# ADSP-SC83xW_HPC register map
Vendor: Analog Devices; Series: ADSP-SC83xW_HPC; File version: 3.0.3.517
CPU: 
Registers are 32-bit, read-write, reset 0x0 unless marked. A register's access mark holds for its fields unless they carry their own. Offsets are from the block's base; [hi:lo] are bit positions; {n}, {i} and the like mark numbered series; 'fields as' and 'values as' point back to an identical list.

## EMAC0 (part 4 of 4) — RGMII, RMII, MII Ethernet Controller
Base 0x31040000
{0xB80+0x10*i} PPS[{i}]_TGTM_SEC (i=0..3) — PPS n Target Time Seconds Register
  [31:0] TSTRH range 0x00000000..0xFFFFFFFF — PPS Target Time Seconds Register
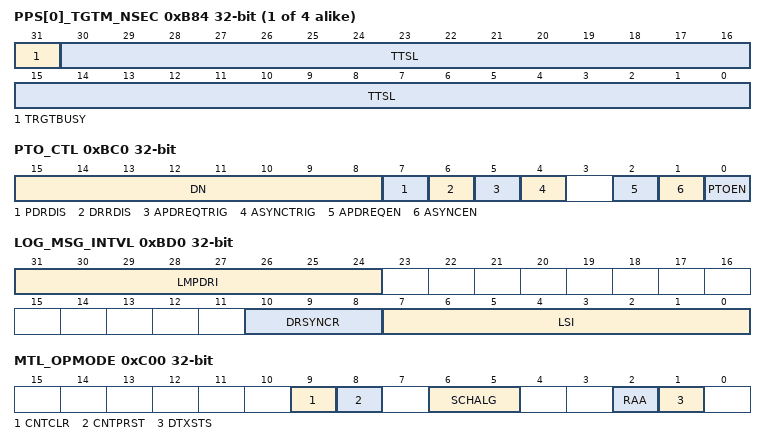
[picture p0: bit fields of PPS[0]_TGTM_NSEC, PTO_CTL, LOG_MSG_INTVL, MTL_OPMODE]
{0xB84+0x10*i} PPS[{i}]_TGTM_NSEC (i=0..3) — PPS n Target Time Nanoseconds Register
  [31] TRGTBUSY — PPS Target Time Register Busy
    0=TRGTBUSY0_INACTIVE (PPS Target Time Register Busy Status is Not Detected); 1=TRGTBUSY0_ACTIVE (PPS Target Time Register Busy is Detected)
  [30:0] TTSL range 0x00000000..0x7FFFFFFF — Target Time Low for PPS Register
{0xB88+0x10*i} PPS[{i}]_INTVL (i=0..3) — PPS n Interval Register
  [31:0] PPSINT range 0x00000000..0xFFFFFFFF — PPS Output Signal Interval
{0xB8C+0x10*i} PPS[{i}]_WID (i=0..3) — PPS n Width Register
  [31:0] PPSWIDTH range 0x00000000..0xFFFFFFFF — PPS Output Signal Width
0xBC0 PTO_CTL — PTP Time Stamp Offload Control Register
  [15:8] DN range 0x00000000..0x000000FF — Domain Number
  [7] PDRDIS — Disable Peer Delay Response Response Generation
    0=PDRDIS_ENABLE (Peer Delay Response Response Generation is Enabled); 1=PDRDIS_DISABLE (Peer Delay Response Response Generation is Disabled)
  [6] DRRDIS — Disable PTO Delay Request/Response Response Generation
    0=DRRDIS_ENABLE (PTO Delay Request/Response Response Generation is Enabled); 1=DRRDIS_DISABLE (PTO Delay Request/Response Response Generation is Disabled)
  [5] APDREQTRIG — Automatic PTP Pdelay_Req Message Trigger
    0=APDREQTRIG_DISABLE (Automatic PTP Pdelay_Req Message Trigger is Disabled); 1=APDREQTRIG_ENABLE (Automatic PTP Pdelay_Req Message Trigger is Enabled)
  [4] ASYNCTRIG — Automatic PTP SYNC Message Trigger
    0=ASYNCTRIG_DISABLE (Automatic PTP SYNC Message Trigger is Disabled); 1=ASYNCTRIG_ENABLE (Automatic PTP SYNC Message Trigger is Enabled)
  [2] APDREQEN — Automatic PTP Pdelay_Req Message Enable
    0=APDREQEN_DISABLE (Automatic PTP Pdelay_Req Message is Disabled); 1=APDREQEN_ENABLE (Automatic PTP Pdelay_Req Message is Enabled)
  [1] ASYNCEN — Automatic PTP SYNC Message Enable
    0=ASYNCEN_DISABLE (Automatic PTP SYNC Message is Disabled); 1=ASYNCEN_ENABLE (Automatic PTP SYNC Message is Enabled)
  [0] PTOEN — PTP Offload Enable
    0=PTOEN_DISABLE (PTP Offload Feature is Disabled); 1=PTOEN_ENABLE (PTP Offload Feature is Enabled)
0xBC4 SRCPRT_IDNTY0 — Source Port Identity 0 Register
  [31:0] SPI0 range 0x00000000..0xFFFFFFFF — Source Port Identity 0
0xBC8 SRCPRT_IDNTY1 — Source Port Identity 1 Register
  [31:0] SPI1 range 0x00000000..0xFFFFFFFF — Source Port Identity 1
0xBCC SRCPRT_IDNTY2 — Source Port Identity 2 Register
  [15:0] SPI2 range 0x00000000..0x0000FFFF — Source Port Identity 2
0xBD0 LOG_MSG_INTVL — PTP Log Message Interval Register
  [31:24] LMPDRI range 0x00000000..0x000000FF — Log Min Pdelay_Req Interval
  [10:8] DRSYNCR — Delay_Req to SYNC Ratio
    0=SYNC1 (DelayReq Generated for Every Received SYNC); 1=SYNC2 (DelayReq Generated Every Alternate Reception of SYNC); 2=SYNC4 (For Every 4 SYNC Messages); 3=SYNC8 (For Every 8 SYNC Messages); 4=SYNC16 (For Every 16 SYNC Messages); 5=SYNC32 (For Every 32 SYNC Messages)
  [7:0] LSI range 0x00000000..0x000000FF — Log Sync Interval
0xC00 MTL_OPMODE — MTL Operation Mode Register
  [9] CNTCLR — Counters Reset
    0=CNTCLR_DISABLE (Counters are Not Reset); 1=CNTCLR_ENABLE (All Counters are Reset)
  [8] CNTPRST — Counters Preset
    0=CNTPRST_DISABLE (Disable); 1=CNTPRST_ENABLE (Enable)
  [6:5] SCHALG — Tx Scheduling Algorithm
    0=WRR (WRR Algorithm); 1=WFQ (WFQ Algorithm); 2=DWRR (DWRR Algorithm); 3=SCHALG_SP (Strict Priority Algorithm)
  [2] RAA — Receive Arbitration Algorithm
    0=RAA_SP (Strict Priority (SP).); 1=WSP (Weighted Strict Priority (WSP))
  [1] DTXSTS — Drop Transmit Status
    0=DTXSTS_DISABLE (Disable); 1=DTXSTS_ENABLE (Enable)
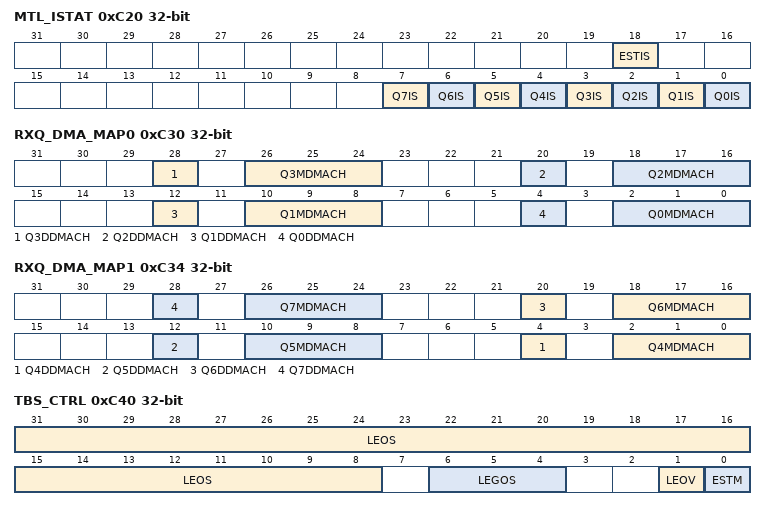
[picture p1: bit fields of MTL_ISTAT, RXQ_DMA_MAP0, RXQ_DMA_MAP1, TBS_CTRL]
0xC20 MTL_ISTAT — MTL Interrupt Status Register
  [18] ESTIS ro — EST (TAS- 802.1Qbv) Interrupt Status
    0=ESTIS_INACTIVE (EST (TAS- 802.1Qbv) Interrupt Status Not Detected); 1=ESTIS_ACTIVE (EST (TAS- 802.1Qbv) Interrupt Status Detected)
  [n] Q{n}IS ro (n=0..7) — Queue {n} Interrupt Status
    0=Q{n}IS_INACTIVE (Status Not Detected); 1=Q{n}IS_ACTIVE (Status Detected)
0xC30 RXQ_DMA_MAP0 — Receive Queue to DMA Channel Mapping Register 0
  [28] Q3DDMACH — Queue 3 Enabled for Dynamic (per Packet) DMA Channel Selection
    0=Q3DDMACH_DISABLE (Disable); 1=Q3DDMACH_ENABLE (Enable)
  [8n+2:8n] Q{n}MDMACH (n=0..3) — Queue {n} Mapped to DMA Channel
  [20] Q2DDMACH — Queue 2 Enabled for DA-based DMA Channel Selection
    0=Q2DDMACH_DISABLE (Disable); 1=Q2DDMACH_ENABLE (Enable)
  [12] Q1DDMACH — Queue 1 Enabled for DA-based DMA Channel Selection
    0=Q1DDMACH_DISABLE (Disable); 1=Q1DDMACH_ENABLE (Enable)
  [4] Q0DDMACH — Queue 0 Enabled for DA-based DMA Channel Selection
    0=Q0DDMACH_DISABLE (Disable); 1=Q0DDMACH_ENABLE (Enable)
0xC34 RXQ_DMA_MAP1 — Receive Queue to DMA Channel Mapping Register 1
  [8n-28] Q{n}DDMACH (n=4..7) — Queue {n} Enabled for DA-based DMA Channel Selection
    0=Q{n}DDMACH_DISABLE (Disable); 1=Q{n}DDMACH_ENABLE (Enable)
  [8n-30:8n-32] Q{n}MDMACH (n=4..7) — Queue {n} Mapped to DMA Channel
0xC40 TBS_CTRL — MTL Time Based Scheduling Control Register
  [31:8] LEOS range 0x00000000..0x00FFFFFF — Launch Expiry Offset
  [6:4] LEGOS range 0x00000000..0x00000007 — Launch Expiry GSN Offset
  [1] LEOV — Launch Expiry Offset Valid
    0=INVALID (LEOS Field is Invalid); 1=VALID (LEOS Field is Valid)
  [0] ESTM — EST Offset Mode
    0=ESTM_DISABLE (Disabled); 1=ESTM_ENABLE (Enabled)
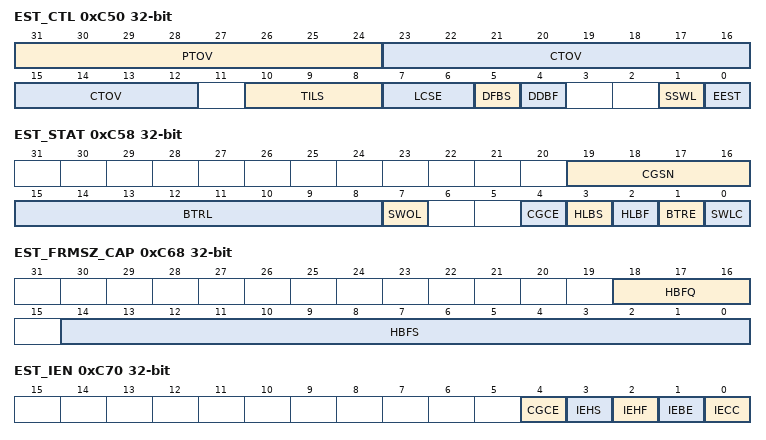
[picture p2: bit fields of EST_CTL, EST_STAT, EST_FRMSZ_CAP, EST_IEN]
0xC50 EST_CTL — EST Control Register
  [31:24] PTOV range 0x00000000..0x000000FF — PTP Time Offset Value
  [23:12] CTOV range 0x00000000..0x00000FFF — Current Time Offset Value
  [10:8] TILS range 0x00000000..0x00000007 — Time Interval Left Shift Amount
  [7:6] LCSE — Loop Count to Report Scheduling Error
    0=M_4_ITERNS (4 Iterations); 1=M_8_ITERNS (8 Iterations); 2=M_16_ITERNS (16 Iterations); 3=M_32_ITERNS (32 Iterations)
  [5] DFBS — Drop Frames Causing Scheduling Error
    0=DFBS_DONT_DROP (Do Not Drop Frames Causing Scheduling Error); 1=DFBS_DROP (Drop Frames Causing Scheduling Error)
  [4] DDBF — Do Not Drop Frames During Frame Size Error
    0=DDBF_DROP (Drop Frames During Frame Size Error); 1=DDBF_DONT_DROP (Do Not Drop Frames During Frame Size Error)
  [1] SSWL — Switch to S/W Owned List
    0=SSWL_DISABLE (Switch to S/W Owned List is Disabled); 1=SSWL_ENABLE (Switch to S/W Owned List is Enabled)
  [0] EEST — Enable EST
    0=EEST_DISABLE (EST is Disabled); 1=EEST_ENABLE (EST is Enabled)
0xC54 EST_EXT_CTL — EST Extended Control Register
  [5:0] OVHD range 0x00000000..0x0000003F — Overhead Bytes Value
0xC58 EST_STAT — EST Status Register
  [19:16] CGSN ro — Current GCL Slot Number
  [15:8] BTRL ro — BTR Error Loop Count
  [7] SWOL ro — S/W Owned List
    0=SWOL_INACTIVE (Gate Control List Number "0" is Owned by Software); 1=SWOL_ACTIVE (Gate Control List Number "1" is Owned by Software)
  [4] CGCE — Constant Gate Control Error
    0=CGCE_INACTIVE (Constant Gate Control Error Not Detected); 1=CGCE_ACTIVE (Constant Gate Control Error Detected)
  [3] HLBS ro — Head-Of-Line Blocking Due to Scheduling
    0=HLBS_INACTIVE (Head-Of-Line Blocking Due to Scheduling Not Detected); 1=HLBS_ACTIVE (Head-Of-Line Blocking Due to Scheduling Detected)
  [2] HLBF ro — Head-Of-Line Blocking Due to Frame Size
    0=HLBF_INACTIVE (Head-Of-Line Blocking Due to Frame Size Not Detected); 1=HLBF_ACTIVE (Head-Of-Line Blocking Due to Frame Size Detected)
  [1] BTRE — BTR Error
    0=BTRE_INACTIVE (BTR Error Not Detected); 1=BTRE_ACTIVE (BTR Error Detected)
  [0] SWLC — Switch to S/W Owned List Complete
    0=SWLC_INACTIVE (Switch to S/W Owned List Complete Not Detected); 1=SWLC_ACTIVE (Switch to S/W Owned List Complete Detected)
0xC60 EST_SCH_ERR — EST Scheduling Error Register
  [7:0] SEQN range 0x00000000..0x000000FF — Schedule Error Queue Number
0xC64 EST_FRMSZ_ERR — EST Frame Size Error Register
  [7:0] FEQN range 0x00000000..0x000000FF — Frame Size Error Queue Number
0xC68 EST_FRMSZ_CAP — EST Frame Size Capture Register
  [18:16] HBFQ ro — Queue Number of HLBF
  [14:0] HBFS ro — Frame Size of HLBF
0xC70 EST_IEN — EST Interrupt Enable Register
  [4] CGCE — Interrupt Enable for CGCE
    0=CGCE_DISABLE (Interrupt for CGCE is Disabled); 1=CGCE_ENABLE (Interrupt for CGCE is Enabled)
  [3] IEHS — Interrupt Enable for HLBS
    0=IEHS_DISABLE (Interrupt for HLBS is Disabled); 1=IEHS_ENABLE (Interrupt for HLBS is Enabled)
  [2] IEHF — Interrupt Enable for HLBF
    0=IEHF_DISABLE (Interrupt for HLBF is Disabled); 1=IEHF_ENABLE (Interrupt for HLBF is Enabled)
  [1] IEBE — Interrupt Enable for BTR Error
    0=IEBE_DISABLE (Interrupt for BTR Error is Disabled); 1=IEBE_ENABLE (Interrupt for BTR Error is Enabled)
  [0] IECC — Interrupt Enable for Switch List
    0=IECC_DISABLE (Interrupt for Switch List is Disabled); 1=IECC_ENABLE (Interrupt for Switch List is Enabled)
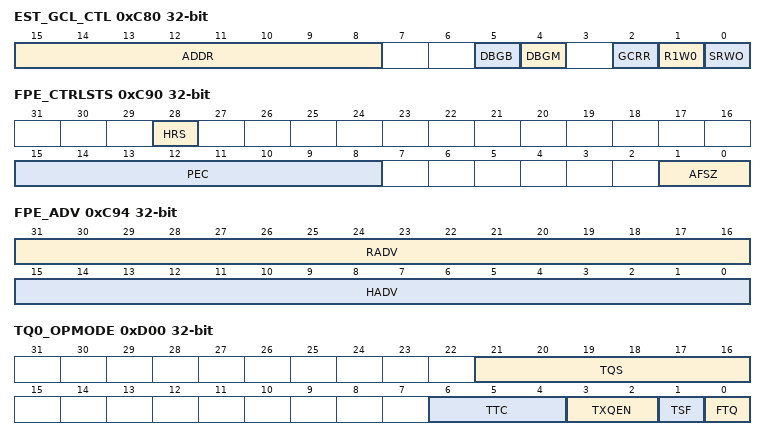
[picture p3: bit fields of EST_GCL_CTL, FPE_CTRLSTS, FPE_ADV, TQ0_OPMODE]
0xC80 EST_GCL_CTL — EST Gate Control List Control Register
  [15:8] ADDR range 0x00000000..0x000000FF — Gate Control List Address
  [5] DBGB — Debug Mode Bank Select
    0=BANK0 (R/W in Debug Mode Should Be Directed to Bank 0); 1=BANK1 (R/W in Debug Mode Should Be Directed to Bank 1)
  [4] DBGM — Debug Mode
    0=DBGM_DISABLE (Debug Mode is Disabled); 1=DBGM_ENABLE (Debug Mode is Enabled)
  [2] GCRR — Gate Control Related Registers
    0=GCRR_DISABLE (Gate Control Related Registers are Disabled); 1=GCRR_ENABLE (Gate Control Related Registers are Enabled)
  [1] R1W0 — Read/Write Operation
    0=WRITE (Write Operation); 1=READ (Read Operation)
  [0] SRWO — Start Read/Write Operation
    0=SRWO_DISABLE (Start Read/Write Op Disabled); 1=SRWO_ENABLE (Start Read/Write Op Enabled)
0xC84 EST_GCL_DAT — EST Gate Control List Data Register
  [31:0] GCD range 0x00000000..0xFFFFFFFF — Gate Control Data
0xC90 FPE_CTRLSTS — MTL Frame Preemption Control and Status Register
  [28] HRS ro — Hold/Release Status
    0=SET_REL (Release); 1=SET_HOLD (Hold)
  [15:8] PEC range 0x00000000..0x000000FF — Preemption Classification
  [1:0] AFSZ range 0x00000000..0x00000003 — Additional Fragment Size
0xC94 FPE_ADV — Frame Preemption Advance Register
  [31:16] RADV range 0x00000000..0x0000FFFF — Release Advance
  [15:0] HADV range 0x00000000..0x0000FFFF — Hold Advance
0xD00 TQ0_OPMODE — Transmit Queue 0 Operation Mode Register
  [21:16] TQS range 0x00000000..0x0000003F — Transmit Queue Size
  [6:4] TTC — Transmit Threshold Control
    0=M_32BYTES (32); 1=M_64BYTES (64); 2=M_96BYTES (96); 3=M_128BYTES (128); 4=M_192BYTES (192); 5=M_256BYTES (256); 6=M_384BYTES (384); 7=M_512BYTES (512)
  [3:2] TXQEN — Transmit Queue Enable
    0=TXQEN_DISABLE (Not Enabled); 1=EN_IF_AV (Enable in AV Mode (Reserved in Non-AV)); 2=TXQEN_ENABLE (Enabled)
  [1] TSF — Transmit Store and Forward
    0=TSF_DISABLE (Transmit Store and Forward is Disabled); 1=TSF_ENABLE (Transmit Store and Forward is Enabled)
  [0] FTQ — Flush Transmit Queue
    0=FTQ_DISABLE (Flush Transmit Queue is Disabled); 1=FTQ_ENABLE (Flush Transmit Queue is Enabled)
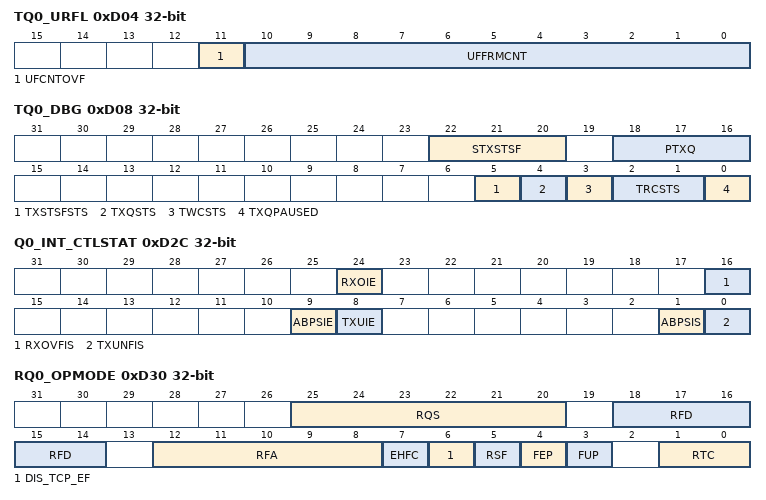
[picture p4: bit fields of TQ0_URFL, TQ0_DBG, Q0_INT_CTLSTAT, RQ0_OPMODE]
0xD04 TQ0_URFL — Transmit Queue 0 Underflow Packet Counter Register
  [11] UFCNTOVF ro — Overflow Bit for Underflow Packet Counter
    0=UFCNTOVF_INACTIVE (Overflow Not Detected for Underflow Packet Counter); 1=UFCNTOVF_ACTIVE (Overflow Detected for Underflow Packet Counter)
  [10:0] UFFRMCNT ro — Underflow Packet Counter
0xD08 TQ0_DBG — Transmit Queue 0 Debug Register
  [22:20] STXSTSF ro — Number of Status Words in Tx Status FIFO of Queue
  [18:16] PTXQ ro — Number of Packets in the Transmit Queue
  [5] TXSTSFSTS ro — MTL Tx Status FIFO Full Status
    0=TXSTSFSTS_INACTIVE (MTL Tx Status FIFO Full Status is Not Detected); 1=TXSTSFSTS_ACTIVE (MTL Tx Status FIFO Full Status is Detected)
  [4] TXQSTS ro — MTL Tx Queue Not Empty Status
    0=TXQSTS_INACTIVE (MTL Tx Queue Not Empty Status is Not Detected); 1=TXQSTS_ACTIVE (MTL Tx Queue Not Empty Status is Detected)
  [3] TWCSTS ro — MTL Tx Queue Write Controller Status
    0=TWCSTS_INACTIVE (MTL Tx Queue Write Controller Status is Not Detected); 1=TWCSTS_ACTIVE (MTL Tx Queue Write Controller Status is Detected)
  [2:1] TRCSTS ro — MTL Tx Queue Read Controller Status
    0=IDLE (Idle State); 1=READ (Read State (Transferring Data to the MAC Transmitter)); 2=WAIT (Waiting for Pending Tx Status from the MAC Transmitter); 3=FLUSH (Flushing the Tx Queue Because of the Packet Abort Request from the MAC)
  [0] TXQPAUSED ro — Transmit Queue in Pause
    0=TXQPAUSED_INACTIVE (Transmit Queue in Pause Status is Not Detected); 1=TXQPAUSED_ACTIVE (Transmit Queue in Pause Status is Detected)
0xD14 TQ0_ETS_STAT — Transmit Queue 0 ETS Status Register
  [23:0] ABS ro — Average Bits per Slot
0xD18 TQ0_QTMWGT — Transmit Queue 0 IdleSlopeCredit, Quantum or Weights Register
  [20:0] ISCQW range 0x00000000..0x001FFFFF — Quantum or Weights
0xD2C Q0_INT_CTLSTAT — Queue 0 Interrupt Control and Status Register
  [24] RXOIE — Receive Queue Overflow Interrupt Enable
    0=RXOIE_DISABLE (Receive Queue Overflow Interrupt is Disabled); 1=RXOIE_ENABLE (Receive Queue Overflow Interrupt is Enabled)
  [16] RXOVFIS — Receive Queue Overflow Interrupt Status
    0=RXOVFIS_INACTIVE (Receive Queue Overflow Interrupt Status Not Detected); 1=RXOVFIS_ACTIVE (Receive Queue Overflow Interrupt Status Detected)
  [9] ABPSIE — Average Bits per Slot Interrupt Enable
    0=ABPSIE_DISABLE (Average Bits per Slot Interrupt is Disabled); 1=ABPSIE_ENABLE (Average Bits per Slot Interrupt is Enabled)
  [8] TXUIE — Transmit Queue Underflow Interrupt Enable
    0=TXUIE_DISABLE (Transmit Queue Underflow Interrupt Status is Disabled); 1=TXUIE_ENABLE (Transmit Queue Underflow Interrupt Status is Enabled)
  [1] ABPSIS — Average Bits per Slot Interrupt Status
    0=ABPSIS_INACTIVE (Average Bits per Slot Interrupt Status Not Detected); 1=ABPSIS_ACTIVE (Average Bits per Slot Interrupt Status Detected)
  [0] TXUNFIS — Transmit Queue Underflow Interrupt Status
    0=TXUNFIS_INACTIVE (Transmit Queue Underflow Interrupt Status Not Detected); 1=TXUNFIS_ACTIVE (Transmit Queue Underflow Interrupt Status Detected)
0xD30 RQ0_OPMODE — Receive Queue 0 Operation Mode Register
  [25:20] RQS range 0x00000000..0x0000003F — Receive Queue Size
  [18:14] RFD range 0x00000000..0x0000001F — Threshold for Deactivating Flow Control
  [12:8] RFA range 0x00000000..0x0000001F — Threshold for Activating Flow Control
  [7] EHFC — Enable Hardware Flow Control
    0=EHFC_DISABLE (Hardware Flow Control is Disabled); 1=EHFC_ENABLE (Hardware Flow Control is Enabled)
  [6] DIS_TCP_EF — Disable Dropping of TCP/IP Checksum Error Packets
    0=DIS_TCP_EF_ENABLE (Dropping of TCP/IP Checksum Error Packets is Enabled); 1=DIS_TCP_EF_DISABLE (Dropping of TCP/IP Checksum Error Packets is Disabled)
  [5] RSF — Receive Queue Store and Forward
    0=RSF_DISABLE (Receive Queue Store and Forward is Disabled); 1=RSF_ENABLE (Receive Queue Store and Forward is Enabled)
  [4] FEP — Forward Error Packets
    0=FEP_DISABLE (Forward Error Packets is Disabled); 1=FEP_ENABLE (Forward Error Packets is Enabled)
  [3] FUP — Forward Undersized Good Packets
    0=FUP_DISABLE (Forward Undersized Good Packets is Disabled); 1=FUP_ENABLE (Forward Undersized Good Packets is Enabled)
  [1:0] RTC — Receive Queue Threshold Control
    0=M_64BYTE (64); 1=M_32BYTE (32); 2=M_96BYTE (96); 3=M_128BYTE (128)
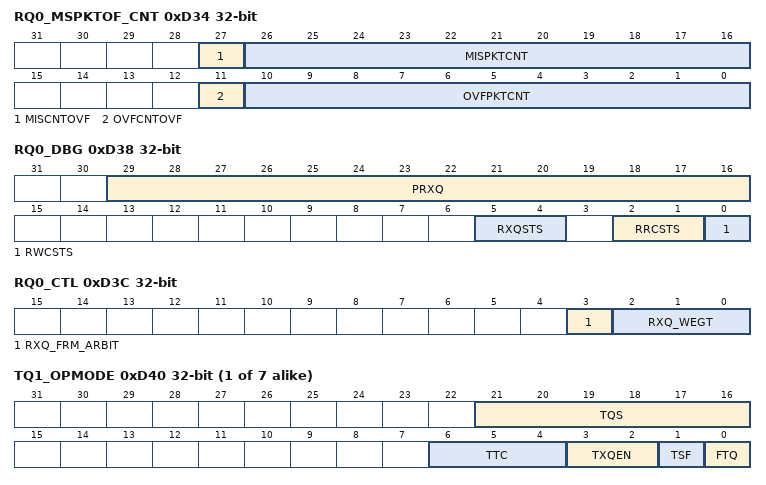
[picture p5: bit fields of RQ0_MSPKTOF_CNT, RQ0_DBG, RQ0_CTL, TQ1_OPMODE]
0xD34 RQ0_MSPKTOF_CNT — Receive Queue 0 Missed Packet and Overflow Counter Register
  [27] MISCNTOVF ro — Missed Packet Counter Overflow Bit
    0=MISCNTOVF_INACTIVE (Missed Packet Counter Overflow Not Detected); 1=MISCNTOVF_ACTIVE (Missed Packet Counter Overflow Detected)
  [26:16] MISPKTCNT ro — Missed Packet Counter
  [11] OVFCNTOVF ro — Overflow Counter Overflow Bit
    0=OVFCNTOVF_INACTIVE (Overflow Counter Overflow Not Detected); 1=OVFCNTOVF_ACTIVE (Overflow Counter Overflow Detected)
  [10:0] OVFPKTCNT ro — Overflow Packet Counter
0xD38 RQ0_DBG — Receive Queue 0 Debug Register
  [29:16] PRXQ ro — Number of Packets in Receive Queue
  [5:4] RXQSTS ro — MTL Rx Queue Fill-Level Status
    0=EMPTY (Rx Queue Empty); 1=BLW_THR (Rx Queue Fill-level Below Flow-control Deactivate Threshold); 2=ABV_THR (Rx Queue Fill-level Above Flow-control Activate Threshold); 3=FULL (Rx Queue Full)
  [2:1] RRCSTS ro — MTL Rx Queue Read Controller State
    0=IDLE (Idle State); 1=READ_DATA (Reading Packet Data); 2=READ_STS (Reading Packet Status (or Timestamp)); 3=FLUSH (Flushing the Packet Data and Status)
  [0] RWCSTS ro — MTL Rx Queue Write Controller Active Status
    0=RWCSTS_INACTIVE (MTL Rx Queue Write Controller Active Status Not Detected); 1=RWCSTS_ACTIVE (MTL Rx Queue Write Controller Active Status Detected)
0xD3C RQ0_CTL — Receive Queue Control Register
  [3] RXQ_FRM_ARBIT — Receive Queue Packet Arbitration
    0=RXQ_FRM_ARBIT_DISABLE (Receive Queue Packet Arbitration is Disabled); 1=RXQ_FRM_ARBIT_ENABLE (Receive Queue Packet Arbitration is Enabled)
  [2:0] RXQ_WEGT range 0x00000000..0x00000007 — Receive Queue Weight
{0xD00+0x40*i} TQ{i}_OPMODE (i=1..7) — Transmit Queue n Operation Mode Register
  fields as TQ0_OPMODE
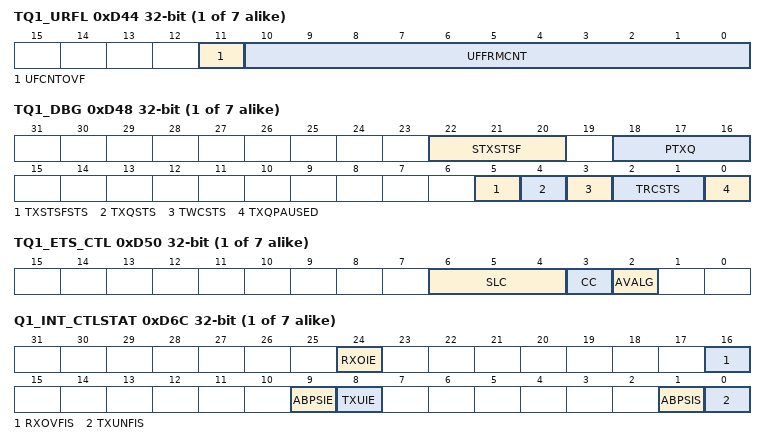
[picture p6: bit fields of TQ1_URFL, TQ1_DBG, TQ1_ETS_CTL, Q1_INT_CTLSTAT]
{0xD04+0x40*i} TQ{i}_URFL (i=1..7) — Transmit Queue n Underflow Packet Counter Register
  fields as TQ0_URFL
{0xD08+0x40*i} TQ{i}_DBG (i=1..7) — Transmit Queue n Debug Register
  [22:20] STXSTSF ro — Number of Status Words in Tx Status FIFO of Queue
  [18:16] PTXQ ro — Number of Packets in the Transmit Queue
  [5] TXSTSFSTS ro — MTL Tx Status FIFO Full Status
    0=TXSTSFSTS_INACTIVE (Status Not Detected); 1=TXSTSFSTS_ACTIVE (Status Detected)
  [4] TXQSTS ro — MTL Tx Queue Not Empty Status
    0=TXQSTS_INACTIVE (Status Not Detected); 1=TXQSTS_ACTIVE (Status Detected)
  [3] TWCSTS ro — MTL Tx Queue Write Controller Status
    0=TWCSTS_INACTIVE (Status Not Detected); 1=TWCSTS_ACTIVE (Status Detected)
  [2:1] TRCSTS ro — MTL Tx Queue Read Controller Status
    0=IDLE (Idle State); 1=READ (Read State (Transferring data to the MAC transmitter)); 2=WAIT (Wait for pending Tx status from the MAC transmitter); 3=FLUSH (Flush the Tx queue because of the packet abort request from the MAC)
  [0] TXQPAUSED ro — Transmit Queue in Pause
    values as TQ0_DBG.TXQPAUSED
{0xD10+0x40*i} TQ{i}_ETS_CTL (i=1..7) — Transmit Queue n ETS Control Register
  [6:4] SLC — Slot Count
    0=M_1_SLOT (1 Slot); 1=M_2_SLOT (2 Slots); 2=M_4_SLOT (4 Slots); 3=M_8_SLOT (8 Slots); 4=M_16_SLOT (16 Slots)
  [3] CC — Credit Control
    0=CC_DISABLE (Credit Control is Disabled); 1=CC_ENABLE (Credit Control is Enabled)
  [2] AVALG — AV Algorithm
    0=AVALG_DISABLE (CBS Algorithm is Disabled); 1=AVALG_ENABLE (CBS Algorithm is Enabled)
{0xD14+0x40*i} TQ{i}_ETS_STAT (i=1..7) — Transmit Queue n ETS Status Register
  [23:0] ABS ro — Average Bits per Slot
{0xD18+0x40*i} TQ{i}_QTMWGT (i=1..7) — Transmit Queue n IdleSlopeCredit, Quantum or Weights Register
  [20:0] ISCQW range 0x00000000..0x001FFFFF — IdleSlopeCredit, Quantum or Weights
{0xD1C+0x40*i} TQ{i}_SSCRDT (i=1..7) — Transmit Queue n SendSlopeCredit Register
  [13:0] SSC range 0x00000000..0x00003FFF — SendSlopeCredit Value
{0xD20+0x40*i} TQ{i}_HICRDT (i=1..7) — Transmit Queue n CBS HiCredit Register
  [28:0] HC range 0x00000000..0x1FFFFFFF — HiCredit Value
{0xD24+0x40*i} TQ{i}_LOCRDT (i=1..7) — Transmit Queue n CBS LoCredit Register
  [28:0] LC range 0x00000000..0x1FFFFFFF — LoCredit Value
{0xD2C+0x40*i} Q{i}_INT_CTLSTAT (i=1..7) — Queue n Interrupt Control and Status Register
  [24] RXOIE — Receive Queue Overflow Interrupt Enable
    0=RXOIE_DISABLE (Disabled); 1=RXOIE_ENABLE (Enabled)
  [16] RXOVFIS — Receive Queue Overflow Interrupt Status
    0=RXOVFIS_INACTIVE (Status Not Detected); 1=RXOVFIS_ACTIVE (Status Detected)
  [9] ABPSIE — Average Bits per Slot Interrupt Enable
    0=ABPSIE_DISABLE (Disabled); 1=ABPSIE_ENABLE (Enabled)
  [8] TXUIE — Transmit Queue Underflow Interrupt Enable
    0=TXUIE_DISABLE (Disabled); 1=TXUIE_ENABLE (Enabled)
  [1] ABPSIS — Average Bits per Slot Interrupt Status
    0=ABPSIS_INACTIVE (Status Not Detected); 1=ABPSIS_ACTIVE (Status Detected)
  [0] TXUNFIS — Transmit Queue Underflow Interrupt Status
    0=TXUNFIS_INACTIVE (Status Not Detected); 1=TXUNFIS_ACTIVE (Status Detected)
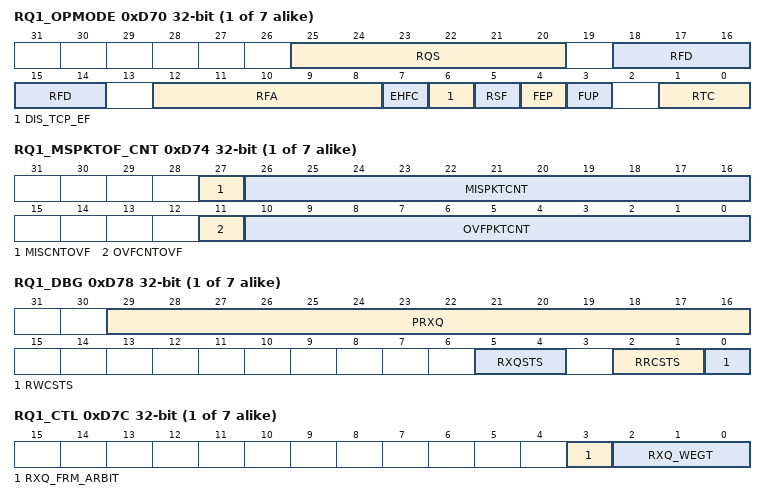
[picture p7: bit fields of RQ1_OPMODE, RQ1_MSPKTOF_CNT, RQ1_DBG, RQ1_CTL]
{0xD30+0x40*i} RQ{i}_OPMODE (i=1..7) — Receive Queue n Operation Mode Register
  [25:20] RQS range 0x00000000..0x0000003F — Receive Queue Size
  [18:14] RFD range 0x00000000..0x0000001F — Threshold for Deactivating Flow Control
  [12:8] RFA range 0x00000000..0x0000001F — Threshold for Activating Flow Control
  [7] EHFC — Hardware Flow Control Enable
    0=EHFC_DISABLE (Disabled); 1=EHFC_ENABLE (Enabled)
  [6] DIS_TCP_EF — Disable Dropping of TCP/IP Checksum Error Packets
    0=DIS_TCP_EF_ENABLE (Enabled); 1=DIS_TCP_EF_DISABLE (Disabled)
  [5] RSF — Receive Queue Store and Forward
    0=RSF_DISABLE (Disabled); 1=RSF_ENABLE (Enabled)
  [4] FEP — Forward Error Packets
    0=FEP_DISABLE (Disabled); 1=FEP_ENABLE (Enabled)
  [3] FUP — Forward Undersized Good Packets
    0=FUP_DISABLE (Disabled); 1=FUP_ENABLE (Enabled)
  [1:0] RTC — Receive Queue Threshold Control
    values as RQ0_OPMODE.RTC
{0xD34+0x40*i} RQ{i}_MSPKTOF_CNT (i=1..7) — Receive Queue n Missed Packet and Overflow Counter Register
  [27] MISCNTOVF ro — Missed Packet Counter Overflow Bit
    0=MISCNTOVF_INACTIVE (Overflow Not Detected); 1=MISCNTOVF_ACTIVE (Overflow Detected)
  [26:16] MISPKTCNT ro — Missed Packet Counter
  [11] OVFCNTOVF ro — Overflow Counter Overflow Bit
    0=OVFCNTOVF_INACTIVE (Overflow Not Detected); 1=OVFCNTOVF_ACTIVE (Overflow Detected)
  [10:0] OVFPKTCNT ro — Overflow Packet Counter
{0xD38+0x40*i} RQ{i}_DBG (i=1..7) — Receive Queue n Debug Register
  [29:16] PRXQ ro — Number of Packets in Receive Queue
  [5:4] RXQSTS ro — MTL Rx Queue Fill-Level Status
    0=EMPTY; 1=BLW_THR (Below Flow Control Deactivate Threshold); 2=ABV_THR (Above Flow Control Activate Threshold); 3=FULL
  [2:1] RRCSTS ro — MTL Rx Queue Read Controller State
    0=IDLE (Idle State); 1=READ_DATA (Reading Packet Data); 2=READ_STS (Reading Packet Status (or Time Stamp)); 3=FLUSH (Flushing the Packet Data and Status)
  [0] RWCSTS ro — MTL Rx Queue Write Controller Active Status
    0=RWCSTS_INACTIVE (Status Not Detected); 1=RWCSTS_ACTIVE (Status Detected)
{0xD3C+0x40*i} RQ{i}_CTL (i=1..7) — Receive Queue n Control Register
  [3] RXQ_FRM_ARBIT — Receive Queue Packet Arbitration
    0=RXQ_FRM_ARBIT_DISABLE (Disabled); 1=RXQ_FRM_ARBIT_ENABLE (Enabled)
  [2:0] RXQ_WEGT range 0x00000000..0x00000007 — Receive Queue Weight
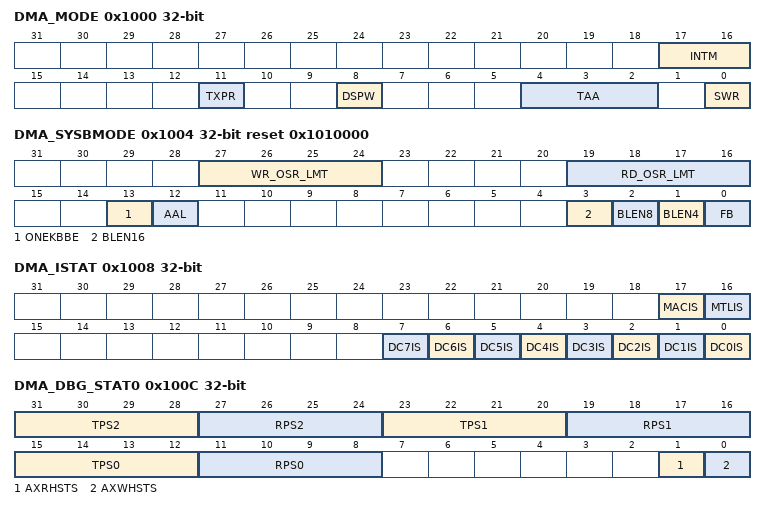
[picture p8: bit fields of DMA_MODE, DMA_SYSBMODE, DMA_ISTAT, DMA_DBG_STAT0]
0x1000 DMA_MODE
  [17:16] INTM — Interrupt Mode
    0=MODE0 (See Above Description); 1=MODE1 (See Above Description); 2=MODE2 (See Above Description)
  [11] TXPR — Transmit Priority
    0=TXPR_DISABLE (Transmit Priority is Disabled); 1=TXPR_ENABLE (Transmit Priority is Enabled)
  [8] DSPW — Descriptor Posted Write
    0=DSPW_DISABLE (Disable); 1=DSPW_ENABLE (Enable)
  [4:2] TAA — Transmit Arbitration Algorithm
    0=FP (Fixed Priority (Channel 0 Has the Lowest Priority and the Last Channel Has the Highest Priority)); 1=WSP (Weighted Strict Priority (WSP)); 2=WRR (Weighted Round-Robin (WRR))
  [0] SWR — Software Reset
    0=SWR_DISABLE (Software Reset is Disabled); 1=SWR_ENABLE (Software Reset is Enabled)
0x1004 DMA_SYSBMODE reset 0x1010000 — DMA System Bus Mode Register
  [27:24] WR_OSR_LMT range 0x00000000..0x0000000F — SCB Maximum Write Outstanding Request Limit
  [19:16] RD_OSR_LMT range 0x00000000..0x0000000F — SCB Maximum Read Outstanding Request Limit
  [13] ONEKBBE — 1 KB Boundary Crossing Enable
    0=ONEKBBE_DISABLE (Disable); 1=ONEKBBE_ENABLE (Enable)
  [12] AAL — Address-Aligned Beats
    0=AAL_DISABLE (Address-Aligned Beats is Disabled); 1=AAL_ENABLE (Address-Aligned Beats is Enabled)
  [3] BLEN16 — SCB Burst Length 16
    0=BLEN16_DISABLE (Disable); 1=BLEN16_ENABLE (Enable)
  [2] BLEN8 — SCB Burst Length 8
    0=BLEN8_DISABLE (Disable); 1=BLEN8_ENABLE (Enable)
  [1] BLEN4 — SCB Burst Length 4
    0=BLEN4_DISABLE (Disable); 1=BLEN4_ENABLE (Enable)
  [0] FB — Fixed Burst Length
    0=FB_DISABLE (Fixed Burst Length is Disabled); 1=FB_ENABLE (Fixed Burst Length is Enabled)
0x1008 DMA_ISTAT — DMA Interrupt Status Register
  [17] MACIS ro — Interrupt Status
    0=MACIS_INACTIVE (MAC Interrupt Status Not Detected); 1=MACIS_ACTIVE (MAC Interrupt Status Detected)
  [16] MTLIS ro — MTL Interrupt Status
    0=MTLIS_INACTIVE (MTL Interrupt Status Not Detected); 1=MTLIS_ACTIVE (MTL Interrupt Status Detected)
  [n] DC{n}IS ro (n=0..7) — DMA Channel {n} Interrupt Status
    0=DC{n}IS_INACTIVE (DMA Channel {n} Interrupt Status Not Detected); 1=DC{n}IS_ACTIVE (DMA Channel {n} Interrupt Status Detected)
0x100C DMA_DBG_STAT0 — DMA Debug Status 0 Register
  [31:28] TPS2 ro — DMA Channel 2 Transmit Process State
    0=TPS2_STOP (Stopped (Reset or Stop Transmit Command Issued)); 1=TPS2_RUN_FTTD (Running (Fetching Tx Transfer Descriptor)); 2=TPS2_RUN_WS (Running (Waiting for Status)); 3=TPS2_RUN_RDS (Running (Reading Data from System Memory Buffer and Queuing It to the Tx Buffer (Tx FIFO))); 4=TPS2_TSTMP_WS (Time Stamp Write State); 6=TPS2_SUSPND (Suspended (Tx Descriptor Unavailable or Tx Buffer Underflow)); 7=TPS2_RUN_CTD (Running (Closing Tx Descriptor))
  [27:24] RPS2 ro — DMA Channel 2 Receive Process State
    0=RPS2_STOP (Stopped (Reset or Stop Receive Command Issued)); 1=RPS2_RUN_FRTD (Running (Fetching Rx Transfer Descriptor)); 3=RPS2_RUN_WRP (Running (Waiting for Rx Packet)); 4=RPS2_SUSPND (Suspended (Rx Descriptor Unavailable)); 5=RPS2_RUN_CRD (Running (Closing the Rx Descriptor)); 6=RPS2_TSTMP (Time Stamp Write State); 7=RPS2_RUN_TRP (Running (Transferring the Received Packet Data from the Rx Buffer to the System Memory))
  [23:20] TPS1 ro — DMA Channel 1 Transmit Process State
    0=TPS1_STOP (Stopped (Reset or Stop Transmit Command Issued)); 1=TPS1_RUN_FTTD (Running (Fetching Tx Transfer Descriptor)); 2=TPS1_RUN_WS (Running (Waiting for Status)); 3=TPS1_RUN_RDS (Running (Reading Data from System Memory Buffer and Queuing It to the Tx Buffer (Tx FIFO))); 4=TPS1_TSTMP_WS (Time Stamp Write State); 6=TPS1_SUSPND (Suspended (Tx Descriptor Unavailable or Tx Buffer Underflow)); 7=TPS1_RUN_CTD (Running (Closing Tx Descriptor))
  [19:16] RPS1 ro — DMA Channel 1 Receive Process State
    0=RPS1_STOP (Stopped (Reset or Stop Receive Command Issued)); 1=RPS1_RUN_FRTD (Running (Fetching Rx Transfer Descriptor)); 3=RPS1_RUN_WRP (Running (Waiting for Rx Packet)); 4=RPS1_SUSPND (Suspended (Rx Descriptor Unavailable)); 5=RPS1_RUN_CRD (Running (Closing the Rx Descriptor)); 6=RPS1_TSTMP (Time Stamp Write State); 7=RPS1_RUN_TRP (Running (Transferring the Received Packet Data from the Rx Buffer to the System Memory))
  [15:12] TPS0 ro — DMA Channel 0 Transmit Process State
    0=TPS0_STOP (Stopped (Reset or Stop Transmit Command Issued)); 1=TPS0_RUN_FTTD (Running (Fetching Tx Transfer Descriptor)); 2=TPS0_RUN_WS (Running (Waiting for Status)); 3=TPS0_RUN_RDS (Running (Reading Data from System Memory Buffer and Queuing It to the Tx Buffer (Tx FIFO))); 4=TPS0_TSTMP_WS (Time Stamp Write State); 6=TPS0_SUSPND (Suspended (Tx Descriptor Unavailable or Tx Buffer Underflow)); 7=TPS0_RUN_CTD (Running (Closing Tx Descriptor))
  [11:8] RPS0 ro — DMA Channel 0 Receive Process State
    0=RPS0_STOP (Stopped (Reset or Stop Receive Command Issued)); 1=RPS0_RUN_FRTD (Running (Fetching Rx Transfer Descriptor)); 3=RPS0_RUN_WRP (Running (Waiting for Rx Packet)); 4=RPS0_SUSPND (Suspended (Rx Descriptor Unavailable)); 5=RPS0_RUN_CRD (Running (Closing the Rx Descriptor)); 6=RPS0_TSTMP (Time Stamp Write State); 7=RPS0_RUN_TRP (Running (Transferring the Received Packet Data from the Rx Buffer to the System Memory))
  [1] AXRHSTS ro — SCB Requester Read Channel Status
    0=AXRHSTS_INACTIVE (Status Not Detected); 1=AXRHSTS_ACTIVE (Status Detected)
  [0] AXWHSTS ro — SCB Requester Write Channel
    0=AXWHSTS_INACTIVE (Status Not Detected); 1=AXWHSTS_ACTIVE (Status Detected)
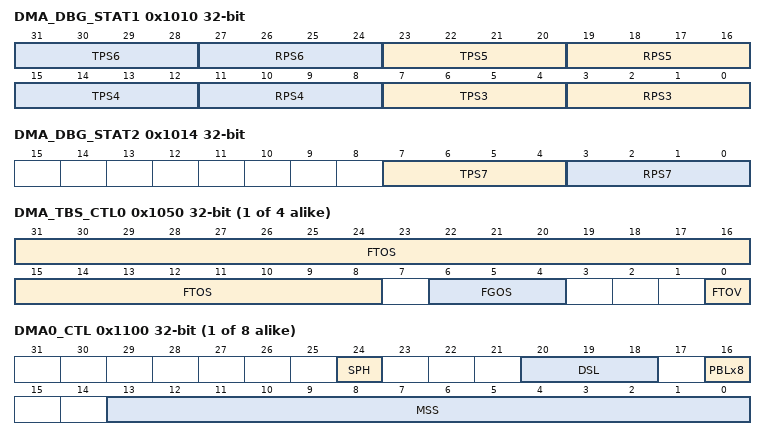
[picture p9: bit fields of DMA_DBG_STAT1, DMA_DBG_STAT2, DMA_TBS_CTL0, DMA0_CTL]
0x1010 DMA_DBG_STAT1 — DMA Debug Status 1 Register
  [8n-17:8n-20] TPS{n} ro (n=3..6) — DMA Channel {n} Transmit Process State
    0=TPS{n}_STOP (Stopped (Reset or Stop Transmit Command Issued)); 1=TPS{n}_RUN_FTTD (Running (Fetching Tx Transfer Descriptor)); 2=TPS{n}_RUN_WS (Running (Waiting for Status)); 3=TPS{n}_RUN_RDS (Running (Reading Data from System Memory Buffer and Queuing It to the Tx Buffer (Tx FIFO))); 4=TPS{n}_TSTMP_WS (Time Stamp Write State); 6=TPS{n}_SUSPND (Suspended (Tx Descriptor Unavailable or Tx Buffer Underflow)); 7=TPS{n}_RUN_CTD (Running (Closing Tx Descriptor))
  [8n-21:8n-24] RPS{n} ro (n=3..6) — DMA Channel {n} Receive Process State
    0=RPS{n}_STOP (Stopped (Reset or Stop Receive Command Issued)); 1=RPS{n}_RUN_FRTD (Running (Fetching Rx Transfer Descriptor)); 3=RPS{n}_RUN_WRP (Running (Waiting for Rx Packet)); 4=RPS{n}_SUSPND (Suspended (Rx Descriptor Unavailable)); 5=RPS{n}_RUN_CRD (Running (Closing the Rx Descriptor)); 6=RPS{n}_TSTMP (Time Stamp Write State); 7=RPS{n}_RUN_TRP (Running (Transferring the Received Packet Data from the Rx Buffer to the System Memory))
0x1014 DMA_DBG_STAT2 — DMA Debug Status 2 Register
  [7:4] TPS7 ro — DMA Channel 7 Transmit Process State
    0=TPS7_STOP (Stopped (Reset or Stop Transmit Command Issued)); 1=TPS7_RUN_FTTD (Running (Fetching Tx Transfer Descriptor)); 2=TPS7_RUN_WS (Running (Waiting for Status)); 3=TPS7_RUN_RDS (Running (Reading Data from System Memory Buffer and Queuing It to the Tx Buffer (Tx FIFO))); 4=TPS7_TSTMP_WS (Time Stamp Write State); 6=TPS7_SUSPND (Suspended (Tx Descriptor Unavailable or Tx Buffer Underflow)); 7=TPS7_RUN_CTD (Running (Closing Tx Descriptor))
  [3:0] RPS7 ro — DMA Channel 7 Receive Process State
    0=RPS7_STOP (Stopped (Reset or Stop Receive Command Issued)); 1=RPS7_RUN_FRTD (Running (Fetching Rx Transfer Descriptor)); 3=RPS7_RUN_WRP (Running (Waiting for Rx Packet)); 4=RPS7_SUSPND (Suspended (Rx Descriptor Unavailable)); 5=RPS7_RUN_CRD (Running (Closing the Rx Descriptor)); 6=RPS7_TSTMP (Time Stamp Write State); 7=RPS7_RUN_TRP (Running (Transferring the Received Packet Data from the Rx Buffer to the System Memory))
{0x1050+4i} DMA_TBS_CTL{i} (i=0..3) — DMA TBS Control {i} Register
  [31:8] FTOS range 0x00000000..0x00FFFFFF — Fetch Time Offset
  [6:4] FGOS range 0x00000000..0x00000007 — Fetch GSN Offset
  [0] FTOV — Fetch Time Offset Valid
    0=INVALID (Fetch Time Offset is Invalid); 1=VALID (Fetch Time Offset is Valid)
{0x1100+0x80*i} DMA{i}_CTL (i=0..7) — DMA Channel n Control Register
  [24] SPH — Split Headers
    0=SPH_DISABLE (Split Headers Feature is Disabled); 1=SPH_ENABLE (Split Headers Feature is Enabled)
  [20:18] DSL range 0x00000000..0x00000007 — Descriptor Skip Length
  [16] PBLx8 — 8xPBL Mode
    0=PBLx8_DISABLE (8xPBL Mode is Disabled); 1=PBLx8_ENABLE (8xPBL Mode is Enabled)
  [13:0] MSS range 0x00000000..0x00003FFF — Maximum Segment Size
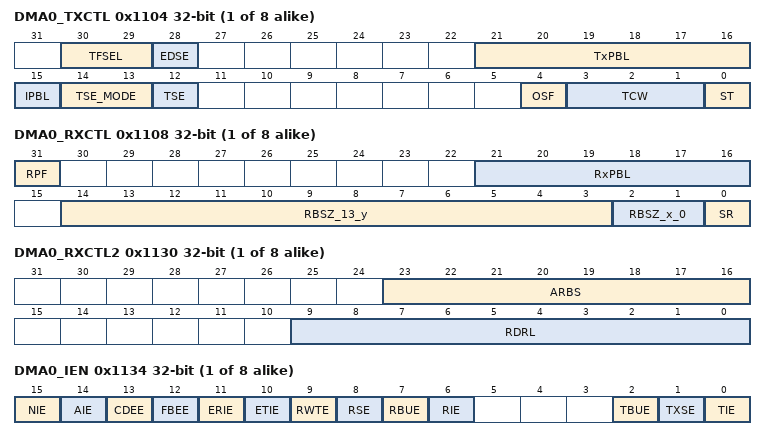
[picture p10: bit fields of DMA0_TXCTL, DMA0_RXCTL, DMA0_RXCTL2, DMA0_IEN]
{0x1104+0x80*i} DMA{i}_TXCTL (i=0..7) — DMA Channel n Transmit Control Register
  [30:29] TFSEL — TBS Fetch Select
  [28] EDSE — Enhanced Descriptor Enable
    0=EDSE_DISABLE (Enhanced Descriptor is Disabled); 1=EDSE_ENABLE (Enhanced Descriptor is Enabled)
  [21:16] TxPBL range 0x00000000..0x0000003F — Transmit Programmable Burst Length
  [15] IPBL — Ignore PBL Requirement
    0=IPBL_DISABLE (Ignore PBL Requirement is Disabled); 1=IPBL_ENABLE (Ignore PBL Requirement is Enabled)
  [14:13] TSE_MODE
    0=TSO_USO; 1=UFOWC (UFO with Checksum.); 2=UFOWOC (UFO Without Checksum.)
  [12] TSE — TCP Segmentation Enabled
    0=TSE_DISABLE (TCP Segmentation is Disabled); 1=TSE_ENABLE (TCP Segmentation is Enabled)
  [4] OSF — Operate on Second Packet
    0=OSF_DISABLE (Operate on Second Packet Disabled); 1=OSF_ENABLE (Operate on Second Packet Enabled)
  [3:1] TCW range 0x00000000..0x00000007 — Transmit Channel Weight
  [0] ST — Start or Stop Transmission Command
    0=ST_STOP (Stop Transmission Command); 1=START (Start Transmission Command)
{0x1108+0x80*i} DMA{i}_RXCTL (i=0..7) — DMA Channel n Receive Control Register
  [31] RPF — Rx Packet Flush
    0=RPF_DISABLE (Rx Packet Flush is Disabled); 1=RPF_ENABLE (Rx Packet Flush is Enabled)
  [21:16] RxPBL range 0x00000000..0x0000003F — Receive Programmable Burst Length
  [14:3] RBSZ_13_y range 0x00000000..0x00000FFF — Receive Buffer Size High
  [2:1] RBSZ_x_0 ro — Receive Buffer Size Low
  [0] SR — Start or Stop Receive
    0=SR_STOP (Stop Receive); 1=START (Start Receive)
{0x1114+0x80*i} DMA{i}_TXDSC_ADDR (i=0..7) — DMA Channel n Transmit Descriptor List Address Register
  [31:2] TDESLA range 0x00000000..0x3FFFFFFF — Start of Transmit List
{0x111C+0x80*i} DMA{i}_RXDSC_ADDR (i=0..7) — DMA Channel n Receive Descriptor List Address Register
  [31:2] RDESLA range 0x00000000..0x3FFFFFFF — Start of Receive List
{0x1120+0x80*i} DMA{i}_TXDSC_TLPTR (i=0..7) — DMA Channel n Transmit Descriptor Tail Pointer Register
  [31:2] TDTP range 0x00000000..0x3FFFFFFF — Transmit Descriptor Tail Pointer
{0x1128+0x80*i} DMA{i}_RXDSC_TLPTR (i=0..7) — DMA Channel n Receive Descriptor Tail Pointer Register
  [31:2] RDTP range 0x00000000..0x3FFFFFFF — Receive Descriptor Tail Pointer
{0x112C+0x80*i} DMA{i}_TXDSC_RLEN (i=0..7) — DMA Channel n Transmit Descriptor Ring Length Register
  [9:0] TDRL range 0x00000000..0x000003FF — Transmit Descriptor Ring Length
{0x1130+0x80*i} DMA{i}_RXCTL2 (i=0..7) — DMA Channel n Extended Receive Control Register
  [23:16] ARBS range 0x00000000..0x000000FF — Alternate Receive Buffer Size
  [9:0] RDRL range 0x00000000..0x000003FF — Receive Descriptor Ring Length
{0x1134+0x80*i} DMA{i}_IEN (i=0..7) — DMA Channel n Interrupt Enable Register
  [15] NIE — Normal Interrupt Summary Enable
    0=NIE_DISABLE (Disable); 1=NIE_ENABLE (Enable)
  [14] AIE — Abnormal Interrupt Summary Enable
    0=AIE_DISABLE (Disable); 1=AIE_ENABLE (Enable)
  [13] CDEE — Context Descriptor Error Enable
    0=CDEE_DISABLE (Disable); 1=CDEE_ENABLE (Enable)
  [12] FBEE — Fatal Bus Error Enable
    0=FBEE_DISABLE (Disable); 1=FBEE_ENABLE (Enable)
  [11] ERIE — Early Receive Interrupt Enable
    0=ERIE_DISABLE (Disable); 1=ERIE_ENABLE (Enable)
  [10] ETIE — Early Transmit Interrupt Enable
    0=ETIE_DISABLE (Disable); 1=ETIE_ENABLE (Enable)
  [9] RWTE — Receive Watchdog Timeout Enable
    0=RWTE_DISABLE (Disable); 1=RWTE_ENABLE (Enable)
  [8] RSE — Receive Stopped Enable
    0=RSE_DISABLE (Disable); 1=RSE_ENABLE (Enable)
  [7] RBUE — Receive Buffer Unavailable Enable
    0=RBUE_DISABLE (Disable); 1=RBUE_ENABLE (Enable)
  [6] RIE — Receive Interrupt Enable
    0=RIE_DISABLE (Disable); 1=RIE_ENABLE (Enable)
  [2] TBUE — Transmit Buffer Unavailable Enable
    0=TBUE_DISABLE (Disable); 1=TBUE_ENABLE (Enable)
  [1] TXSE — Transmit Stopped Enable
    0=TXSE_DISABLE (Disable); 1=TXSE_ENABLE (Enable)
  [0] TIE — Transmit Interrupt Enable
    0=TIE_DISABLE (Disable); 1=TIE_ENABLE (Enable)
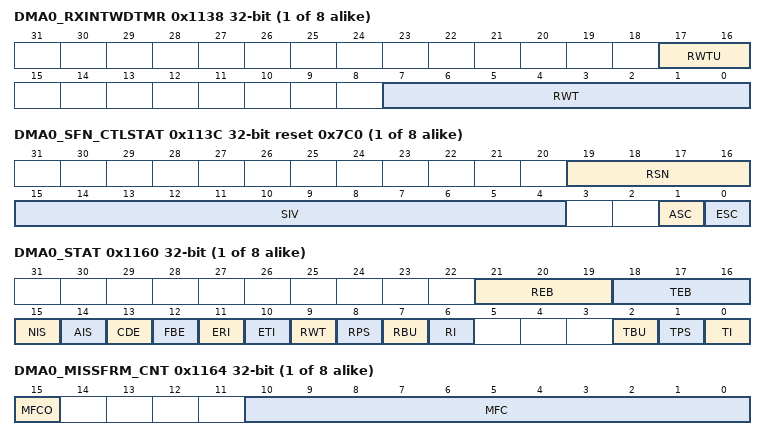
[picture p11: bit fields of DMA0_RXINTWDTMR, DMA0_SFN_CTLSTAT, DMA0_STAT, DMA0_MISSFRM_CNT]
{0x1138+0x80*i} DMA{i}_RXINTWDTMR (i=0..7) — DMA Channel n Receive Interrupt Watchdog Timer Register
  [17:16] RWTU — Receive Interrupt Watchdog Timer Count Units
  [7:0] RWT range 0x00000000..0x000000FF — Receive Interrupt Watchdog Timer Count
{0x113C+0x80*i} DMA{i}_SFN_CTLSTAT reset 0x7C0 (i=0..7) — DMA Channel n Slot Function Control and Status register
  [19:16] RSN ro — Reference Slot Number
  [15:4] SIV range 0x00000000..0x00000FFF — Slot Interval Value
  [1] ASC — Advance Slot Check
    0=ASC_DISABLE (Advance Slot Check is Disabled); 1=ASC_ENABLE (Advance Slot Check is Enabled)
  [0] ESC — Enable Slot Comparison
    0=ESC_DISABLE (Slot Comparison is Disabled); 1=ESC_ENABLE (Slot Comparison is Enabled)
{0x1144+0x80*i} DMA{i}_TXDSC_CUR (i=0..7) — DMA Channel n Current Application Transmit Descriptor Register
  [31:0] CURTDESAPTR ro — Application Transmit Descriptor Address Pointer
{0x114C+0x80*i} DMA{i}_RXDSC_CUR (i=0..7) — DMA Channel n Current Application Receive Descriptor Register
  [31:0] CURRDESAPTR ro — Application Receive Descriptor Address Pointer
{0x1154+0x80*i} DMA{i}_TXBUF_CUR (i=0..7) — DMA Channel n Current Application Transmit Buffer Address Register
  [31:0] CURTBUFAPTR ro — Application Transmit Buffer Address Pointer
{0x115C+0x80*i} DMA{i}_RXBUF_CUR (i=0..7) — DMA Channel n Current Application Receive Buffer Address Register
  [31:0] CURRBUFAPTR ro — Application Receive Buffer Address Pointer
{0x1160+0x80*i} DMA{i}_STAT (i=0..7) — DMA Channel n Status Register
  [21:19] REB ro — Rx DMA Error Bits
  [18:16] TEB ro — Tx DMA Error Bits
  [15] NIS — Normal Interrupt Summary
    0=NIS_INACTIVE (Normal Interrupt Summary Status Not Detected); 1=NIS_ACTIVE (Normal Interrupt Summary Status Detected)
  [14] AIS — Abnormal Interrupt Summary
    0=AIS_INACTIVE (Abnormal Interrupt Summary Status Not Detected); 1=AIS_ACTIVE (Abnormal Interrupt Summary Status Detected)
  [13] CDE — Context Descriptor Error
    0=CDE_INACTIVE (Context Descriptor Error Status Not Detected); 1=CDE_ACTIVE (Context Descriptor Error Status Detected)
  [12] FBE — Fatal Bus Error
    0=FBE_INACTIVE (Fatal Bus Error Status Not Detected); 1=FBE_ACTIVE (Fatal Bus Error Status Detected)
  [11] ERI — Early Receive Interrupt
    0=ERI_INACTIVE (Early Receive Interrupt Status Not Detected); 1=ERI_ACTIVE (Early Receive Interrupt Status Detected)
  [10] ETI — Early Transmit Interrupt
    0=ETI_INACTIVE (Early Transmit Interrupt Status Not Detected); 1=ETI_ACTIVE (Early Transmit Interrupt Status Detected)
  [9] RWT — Receive Watchdog Timeout
    0=RWT_INACTIVE (Receive Watchdog Timeout Status Not Detected); 1=RWT_ACTIVE (Receive Watchdog Timeout Status Detected)
  [8] RPS — Receive Process Stopped
    0=RPS_INACTIVE (Receive Process Stopped Status Not Detected); 1=RPS_ACTIVE (Receive Process Stopped Status Detected)
  [7] RBU — Receive Buffer Unavailable
    0=RBU_INACTIVE (Receive Buffer Unavailable Status Not Detected); 1=RBU_ACTIVE (Receive Buffer Unavailable Status Detected)
  [6] RI — Receive Interrupt
    0=RI_INACTIVE (Receive Interrupt Status Not Detected); 1=RI_ACTIVE (Receive Interrupt Status Detected)
  [2] TBU — Transmit Buffer Unavailable
    0=TBU_INACTIVE (Transmit Buffer Unavailable Status Not Detected); 1=TBU_ACTIVE (Transmit Buffer Unavailable Status Detected)
  [1] TPS — Transmit Process Stopped
    0=TPS_INACTIVE (Transmit Process Stopped Status Not Detected); 1=TPS_ACTIVE (Transmit Process Stopped Status Detected)
  [0] TI — Transmit Interrupt
    0=TI_INACTIVE (Transmit Interrupt Status Not Detected); 1=TI_ACTIVE (Transmit Interrupt Status Detected)
{0x1164+0x80*i} DMA{i}_MISSFRM_CNT (i=0..7) — DMA Channel n Missed Frame Counter Register
  [15] MFCO ro — Overflow Status of the MFC Counter
    0=MFCO_INACTIVE (Miss Frame Counter Overflow Not Occurred); 1=MFCO_ACTIVE (Miss Frame Counter Overflow Occurred)
  [10:0] MFC ro — Dropped Packet Counters
